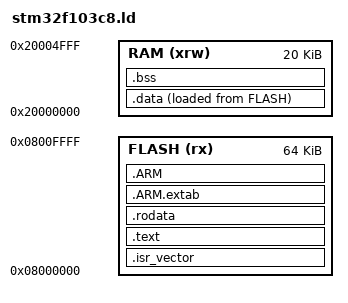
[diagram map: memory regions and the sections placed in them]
/* 链接脚本：STM32F103C8T6，64KB Flash + 20KB RAM（仅用于诊断固件） */
ENTRY(Reset_Handler)

MEMORY
{
  FLASH (rx)  : ORIGIN = 0x08000000, LENGTH = 64K
  RAM   (xrw) : ORIGIN = 0x20000000, LENGTH = 20K
}

_estack = ORIGIN(RAM) + LENGTH(RAM);

SECTIONS
{
  .isr_vector : {
    . = ALIGN(4);
    KEEP(*(.isr_vector))
    . = ALIGN(4);
  } >FLASH

  .text : {
    . = ALIGN(4);
    *(.text)
    *(.text*)
    *(.glue_7)
    *(.glue_7t)
    *(.eh_frame)
    KEEP(*(.init))
    KEEP(*(.fini))
    . = ALIGN(4);
    _etext = .;
  } >FLASH

  .rodata : {
    . = ALIGN(4);
    *(.rodata)
    *(.rodata*)
    . = ALIGN(4);
  } >FLASH

  .ARM.extab : { *(.ARM.extab* .gnu.linkonce.armextab.*) } >FLASH
  .ARM : {
    __exidx_start = .;
    *(.ARM.exidx*)
    __exidx_end = .;
  } >FLASH

  _sidata = LOADADDR(.data);

  .data : {
    . = ALIGN(4);
    _sdata = .;
    *(.data)
    *(.data*)
    . = ALIGN(4);
    _edata = .;
  } >RAM AT> FLASH

  . = ALIGN(4);
  .bss : {
    _sbss = .;
    __bss_start__ = _sbss;
    *(.bss)
    *(.bss*)
    *(COMMON)
    . = ALIGN(4);
    _ebss = .;
    __bss_end__ = _ebss;
  } >RAM

  . = ALIGN(8);
  end = .;
  _end = .;
  __end__ = .;
  PROVIDE(end = .);
}
